AUTOSAR XML (schema 00050)
standard types defined: Boolean
package /ARRoot
  trigger-interface:
    trigger PassiveKeylessEntryLeftTrigger
    trigger PassiveKeylessEntryRightTrigger
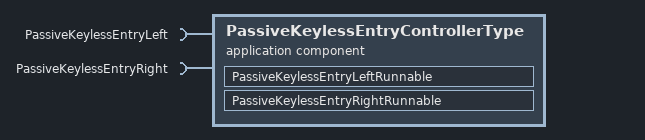
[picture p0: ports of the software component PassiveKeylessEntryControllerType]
  application sw component type PassiveKeylessEntryControllerType
    require port PassiveKeylessEntryLeft
    require port PassiveKeylessEntryRight
    behavior PassiveKeylessEntryIB
      runnable PassiveKeylessEntryLeftRunnable: synchronous-server-call-point=PassiveKeylessEntryLeft.
      runnable PassiveKeylessEntryRightRunnable: synchronous-server-call-point=PassiveKeylessEntryRight.
  swc implementation PassiveKeylessEntryImp: programming-language=C, behavior=PassiveKeylessEntryControllerType/PassiveKeylessEntryIB
  client server interface PassiveKeylessEntryLeftCSIF: client-server-operation=arguments=argument-data-prototype=direction=OUT
  client server interface PassiveKeylessEntryRightCSIF: client-server-operation=arguments=argument-data-prototype=direction=OUT
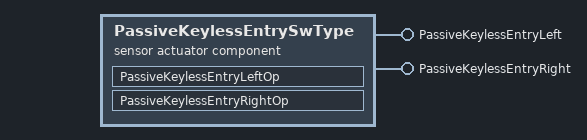
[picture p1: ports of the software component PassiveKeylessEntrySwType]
  sensor actuator sw component type PassiveKeylessEntrySwType
    provide port PassiveKeylessEntryLeft
    provide port PassiveKeylessEntryRight
    behavior PassiveKeylessEntryIB
      runnable PassiveKeylessEntryLeftOp: external-triggering-point=PassiveKeylessEntryLeft.PassiveKeylessEntryLeftTrigger
      runnable PassiveKeylessEntryRightOp: external-triggering-point=PassiveKeylessEntryRight.PassiveKeylessEntryRightTrigger
